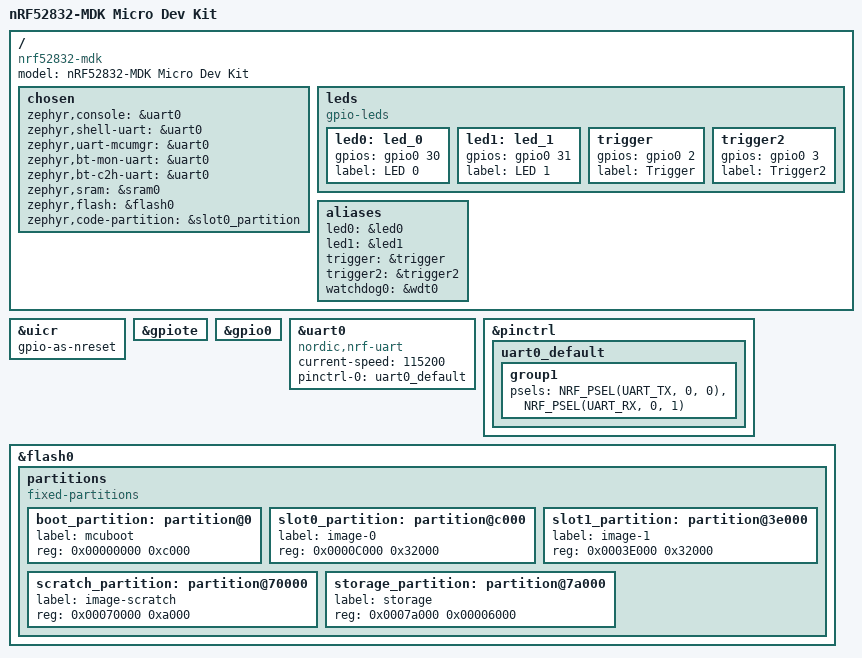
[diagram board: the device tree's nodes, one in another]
/*
 * Copyright (c) 2018 Zelin <zelin@makerdiary.com>
 * Copyright (c) 2018 makerdiary.com.
 *
 * SPDX-License-Identifier: Apache-2.0
 */

 /dts-v1/;
 #include <nordic/nrf52832_qfaa.dtsi>
//  #include "nrf52832_mdk-pinctrl.dtsi"
 #include <zephyr/dt-bindings/input/input-event-codes.h>
 
 / {
	 model = "nRF52832-MDK Micro Dev Kit";
	 compatible = "nrf52832-mdk";
 
	 chosen {
		 zephyr,console = &uart0;
		 zephyr,shell-uart = &uart0;
		 zephyr,uart-mcumgr = &uart0;
		 zephyr,bt-mon-uart = &uart0;
		 zephyr,bt-c2h-uart = &uart0;
		 zephyr,sram = &sram0;
		 zephyr,flash = &flash0;
		 zephyr,code-partition = &slot0_partition;
	 };
 
	 leds {
		compatible = "gpio-leds";
		led0: led_0 {
			gpios = <&gpio0 30 GPIO_ACTIVE_HIGH>;
			label = "LED 0";
		};
		led1: led_1 {
			gpios = <&gpio0 31 GPIO_ACTIVE_HIGH>;
			label = "LED 1";
		};
		trigger: trigger {
			gpios = <&gpio0 2 GPIO_ACTIVE_HIGH>;
			label = "Trigger";
		};
		trigger2: trigger2 {
			gpios = <&gpio0 3 GPIO_ACTIVE_HIGH>;
			label = "Trigger2";
		};
	};
	/* These aliases are provided for compatibility with samples */
	aliases {
		led0 = &led0;
		led1 = &led1;
		trigger = &trigger;
		trigger2 = &trigger2;
        // trigger = &trigger_gpios;
		watchdog0 = &wdt0;
    };

 };
 
 &uicr {
	 gpio-as-nreset;
 };
 
 &gpiote {
	 status = "okay";
 };
 
 &gpio0 {
	 status = "okay";
 };
 
 &uart0 {
	 status = "okay";
	 compatible = "nordic,nrf-uart";
	 current-speed = <115200>;
	 pinctrl-0 = <&uart0_default>;
	//  pinctrl-1 = <&uart0_sleep>;
	 pinctrl-names = "default";
 };
 
 &pinctrl {

	uart0_default: uart0_default {
		group1 {
			psels = <NRF_PSEL(UART_TX, 0, 0)>, <NRF_PSEL(UART_RX, 0, 1)>;
		};
	};
};

//  &i2c0 {
// 	 compatible = "nordic,nrf-twi";
// 	 status = "okay";
// 	 pinctrl-0 = <&i2c0_default>;
// 	 pinctrl-1 = <&i2c0_sleep>;
// 	 pinctrl-names = "default", "sleep";
//  };
 
//  &i2c1 {
// 	 compatible = "nordic,nrf-twi";
// 	 status = "okay";
// 	 pinctrl-0 = <&i2c1_default>;
// 	 pinctrl-1 = <&i2c1_sleep>;
// 	 pinctrl-names = "default", "sleep";
//  };
 
//  &pwm0 {
// 	 status = "okay";
// 	 pinctrl-0 = <&pwm0_default>;
// 	 pinctrl-1 = <&pwm0_sleep>;
// 	 pinctrl-names = "default", "sleep";
//  };
 
 &flash0 {
 
	 partitions {
		 compatible = "fixed-partitions";
		 #address-cells = <1>;
		 #size-cells = <1>;
 
		 boot_partition: partition@0 {
			 label = "mcuboot";
			 reg = <0x00000000 0xc000>;
		 };
		 slot0_partition: partition@c000 {
			 label = "image-0";
			 reg = <0x0000C000 0x32000>;
		 };
		 slot1_partition: partition@3e000 {
			 label = "image-1";
			 reg = <0x0003E000 0x32000>;
		 };
		 scratch_partition: partition@70000 {
			 label = "image-scratch";
			 reg = <0x00070000 0xa000>;
		 };
		 storage_partition: partition@7a000 {
			 label = "storage";
			 reg = <0x0007a000 0x00006000>;
		 };
	 };
 };
 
